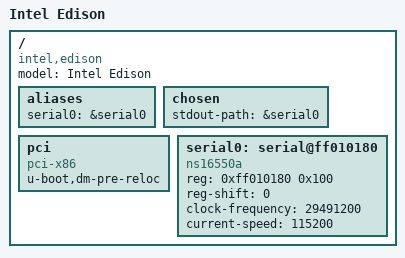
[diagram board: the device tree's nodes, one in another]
/*
 * Copyright (c) 2015 Google, Inc
 *
 * SPDX-License-Identifier:	GPL-2.0+
 */

/dts-v1/;

#include <dt-bindings/gpio/x86-gpio.h>
#include <dt-bindings/interrupt-router/intel-irq.h>

/include/ "skeleton.dtsi"
/include/ "rtc.dtsi"

/ {
	model = "Intel Edison";
	compatible = "intel,edison";

	aliases {
		serial0 = &serial0;
	};

	chosen {
		stdout-path = &serial0;
	};

	pci {
		compatible = "pci-x86";
		#address-cells = <3>;
		#size-cells = <2>;
		u-boot,dm-pre-reloc;
		ranges = <0x02000000 0x0 0x80000000 0x80000000 0 0x40000000
			  0x42000000 0x0 0xc0000000 0xc0000000 0 0x20000000
			  0x01000000 0x0 0x2000 0x2000 0 0xe000>;
	};

	serial0: serial@ff010180 {
		compatible = "ns16550a";
		reg = <0xff010180 0x100>;
		reg-shift = <0>;
		clock-frequency = <29491200>;
		current-speed = <115200>;
	};
};
